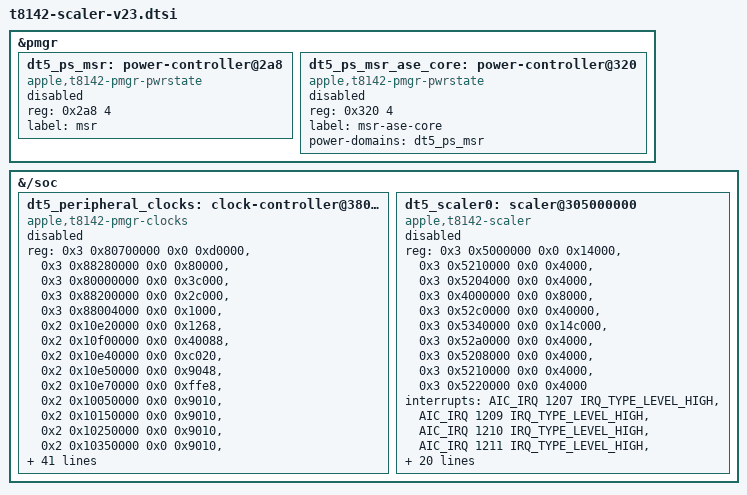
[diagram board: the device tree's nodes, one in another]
// SPDX-License-Identifier: GPL-2.0-only OR MIT
/* Firmware/descriptor scaler family. No direct-MMIO scaler driver fallback. */

&pmgr {
	dt5_ps_msr: power-controller@2a8 {
		compatible = "apple,t8142-pmgr-pwrstate", "apple,t8103-pmgr-pwrstate";
		reg = <0x2a8 4>;
		#power-domain-cells = <0>;
		#reset-cells = <0>;
		label = "msr";
		status = "disabled";
	};
	dt5_ps_msr_ase_core: power-controller@320 {
		compatible = "apple,t8142-pmgr-pwrstate", "apple,t8103-pmgr-pwrstate";
		reg = <0x320 4>;
		#power-domain-cells = <0>;
		#reset-cells = <0>;
		label = "msr-ase-core";
		power-domains = <&dt5_ps_msr>;
		status = "disabled";
	};
};

&{/soc} {
	dt5_peripheral_clocks: clock-controller@380700000 {
		compatible = "apple,t8142-pmgr-clocks", "apple,pmgr-clocks";
		reg = <0x3 0x80700000 0x0 0xd0000>,
		      <0x3 0x88280000 0x0 0x80000>,
		      <0x3 0x80000000 0x0 0x3c000>,
		      <0x3 0x88200000 0x0 0x2c000>,
		      <0x3 0x88004000 0x0 0x1000>,
		      <0x2 0x10e20000 0x0 0x1268>,
		      <0x2 0x10f00000 0x0 0x40088>,
		      <0x2 0x10e40000 0x0 0xc020>,
		      <0x2 0x10e50000 0x0 0x9048>,
		      <0x2 0x10e70000 0x0 0xffe8>,
		      <0x2 0x10050000 0x0 0x9010>,
		      <0x2 0x10150000 0x0 0x9010>,
		      <0x2 0x10250000 0x0 0x9010>,
		      <0x2 0x10350000 0x0 0x9010>,
		      <0x2 0x10450000 0x0 0x9010>,
		      <0x2 0x10550000 0x0 0x9010>,
		      <0x2 0x11e20000 0x0 0x12e8>,
		      <0x2 0x11f00000 0x0 0x40088>,
		      <0x2 0x11e40000 0x0 0xc020>,
		      <0x2 0x11e50000 0x0 0x9048>,
		      <0x2 0x11e70000 0x0 0xffe8>,
		      <0x2 0x11050000 0x0 0x9018>,
		      <0x2 0x11150000 0x0 0x9018>,
		      <0x2 0x11250000 0x0 0x9018>,
		      <0x2 0x11350000 0x0 0x9018>,
		      <0x3 0x80280000 0x0 0x8000>,
		      <0x3 0x88700000 0x0 0x4000>,
		      <0x3 0x88100000 0x0 0xa8000>,
		      <0x4 0x2195c000 0x0 0x4000>,
		      <0x4 0x21960000 0x0 0x4000>,
		      <0x4 0x21974000 0x0 0x4000>,
		      <0x3 0x80208000 0x0 0x8000>,
		      <0x3 0x80700000 0x0 0x18000>,
		      <0x3 0x80728000 0x0 0x4000>,
		      <0x3 0x80724000 0x0 0x4000>,
		      <0x3 0x80764000 0x0 0x4000>,
		      <0x3 0x80780000 0x0 0x4000>,
		      <0x3 0x80760000 0x0 0x4000>,
		      <0x3 0x882b8000 0x0 0x10000>,
		      <0x3 0x882c8000 0x0 0x4000>,
		      <0x3 0x882d0000 0x0 0x8000>,
		      <0x3 0x803c0000 0x0 0x20000>,
		      <0x3 0x80730000 0x0 0x14000>,
		      <0x2 0x11000000 0x0 0xff4000>,
		      <0x4 0x21954000 0x0 0x4000>,
		      <0x3 0x80768000 0x0 0x4000>,
		      <0x3 0x8002c000 0x0 0x4000>,
		      <0x3 0x82000000 0x0 0x1000000>,
		      <0x5 0x80e80000 0x0 0x30000>,
		      <0x5 0x80ec0000 0x0 0x4000>,
		      <0x5 0x80ec0000 0x0 0x8000>,
		      <0x5 0x80e30000 0x0 0x4000>,
		      <0x5 0x80e30000 0x0 0x8000>,
		      <0x2 0x10000000 0x0 0xff4000>;
		#clock-cells = <1>;
		apple,pmgr = <&pmgr>;
		status = "disabled";
	};

	dt5_scaler0: scaler@305000000 {
		compatible = "apple,t8142-scaler", "apple,scaler-v23";
		reg = <0x3 0x5000000 0x0 0x14000>,
		      <0x3 0x5210000 0x0 0x4000>,
		      <0x3 0x5204000 0x0 0x4000>,
		      <0x3 0x4000000 0x0 0x8000>,
		      <0x3 0x52c0000 0x0 0x40000>,
		      <0x3 0x5340000 0x0 0x14c000>,
		      <0x3 0x52a0000 0x0 0x4000>,
		      <0x3 0x5208000 0x0 0x4000>,
		      <0x3 0x5210000 0x0 0x4000>,
		      <0x3 0x5220000 0x0 0x4000>;
		interrupts = <AIC_IRQ 1207 IRQ_TYPE_LEVEL_HIGH>,
		             <AIC_IRQ 1209 IRQ_TYPE_LEVEL_HIGH>,
		             <AIC_IRQ 1210 IRQ_TYPE_LEVEL_HIGH>,
		             <AIC_IRQ 1211 IRQ_TYPE_LEVEL_HIGH>,
		             <AIC_IRQ 1215 IRQ_TYPE_LEVEL_HIGH>,
		             <AIC_IRQ 1216 IRQ_TYPE_LEVEL_HIGH>,
		             <AIC_IRQ 1217 IRQ_TYPE_LEVEL_HIGH>,
		             <AIC_IRQ 1218 IRQ_TYPE_LEVEL_HIGH>,
		             <AIC_IRQ 1219 IRQ_TYPE_LEVEL_HIGH>,
		             <AIC_IRQ 1220 IRQ_TYPE_LEVEL_HIGH>,
		             <AIC_IRQ 1221 IRQ_TYPE_LEVEL_HIGH>,
		             <AIC_IRQ 1222 IRQ_TYPE_LEVEL_HIGH>,
		             <AIC_IRQ 1223 IRQ_TYPE_LEVEL_HIGH>,
		             <AIC_IRQ 1224 IRQ_TYPE_LEVEL_HIGH>,
		             <AIC_IRQ 1225 IRQ_TYPE_LEVEL_HIGH>,
		             <AIC_IRQ 1226 IRQ_TYPE_LEVEL_HIGH>,
		             <AIC_IRQ 1227 IRQ_TYPE_LEVEL_HIGH>,
		             <AIC_IRQ 1228 IRQ_TYPE_LEVEL_HIGH>,
		             <AIC_IRQ 1229 IRQ_TYPE_LEVEL_HIGH>,
		             <AIC_IRQ 1230 IRQ_TYPE_LEVEL_HIGH>;
		iommus = <&dt5_dart_scaler 0>, <&dt5_dart_scaler 1>;
		clocks = <&dt5_peripheral_clocks 399>;
		power-domains = <&dt5_ps_msr>, <&dt5_ps_msr_ase_core>;
		resets = <&dt5_ps_msr>;
		status = "disabled";
	};
};
